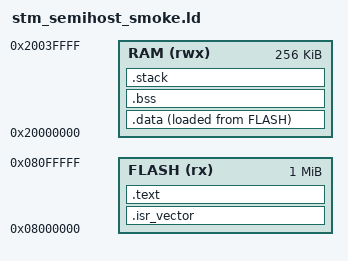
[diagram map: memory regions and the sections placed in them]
ENTRY(_start)

MEMORY
{
    FLASH (rx)  : ORIGIN = 0x08000000, LENGTH = 1024K
    RAM   (rwx) : ORIGIN = 0x20000000, LENGTH = 256K
}

SECTIONS
{
    .isr_vector ORIGIN(FLASH) :
    {
        KEEP(*(.isr_vector))
    } > FLASH

    .text :
    {
        *(.text*)
        *(.rodata*)
    } > FLASH

    .data :
    {
        *(.data*)
    } > RAM AT > FLASH

    .bss (NOLOAD) :
    {
        *(.bss*)
        *(COMMON)
    } > RAM

    .stack (NOLOAD) :
    {
        *(.stack)
    } > RAM
}
